# McBSP1 register map
Vendor: Texas Instruments
Peripheral module from a debugger description file (folder omap36xx).
Registers are 32-bit, access per field, reset values left out (the file's numbers can be read two ways) unless marked. A register's access mark holds for its fields unless they carry their own. Offsets are as the file gives them; lines under a group give offsets from that group; [hi:lo] are bit positions; {n}, {i} and the like mark numbered series; 'fields as' and 'values as' point back to an identical list; <NAME> marks a mode.

## McBSP1
0x00 MCBSPLP_DRR_REG ro — McBSPLP data receive register
  [31:0] DRR — Data receive register
0x08 MCBSPLP_DXR_REG wo — McBSPLP data transmit register
  [31:0] DXR — Data transmit register
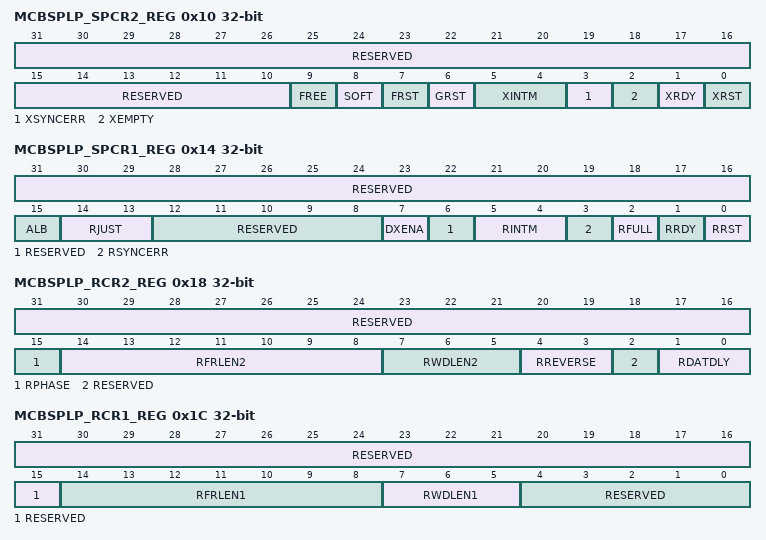
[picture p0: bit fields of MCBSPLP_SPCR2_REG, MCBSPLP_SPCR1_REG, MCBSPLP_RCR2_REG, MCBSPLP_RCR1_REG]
0x10 MCBSPLP_SPCR2_REG — McBSPLP serial port control register 2
  [31:10] RESERVED ro — Read returns 0x0.
  [9] FREE rw — Free Running Mode(When this bit is set, the module ignores the Msuspend input)
    0=Free running mode is disabled; 1=Free running mode is enabled
  [8] SOFT rw — Soft Bit
    0=SOFT Mode is disabled: the McBSP module stops its activity immediately following MSuspend assertion; 1=SOFT Mode is enabled: the McBSP module freezes its state after completion of the current operation when MSuspend is asserted
  [7] FRST rw — Frame-Sync Generator Reset
    0=Frame-synchronization logic is reset. Frame-sync signal FSG is not generated by the sample-rate generator; 1=Frame-sync signal FSG is generated after (FPER+1) number of CLKG clocks; i.e., all frame counters are loaded with their programmed values
  [6] GRST rw — Sample-Rate Generator Reset
    0=SRG is reset; 1=SRG is pulled out of reset. CLKG is driven as per programmed value in SRG registers (SRGR[1,2])
  [5:4] XINTM rw — Transmit Interrupt Mode (legacy)
    0=Transmit interrupt is driven by XRDY; 1=Transmit interrupt generated by end-of-frame; 2=Transmit interrupt generated by a new frame synchronization; 3=Transmit interrupt generated by XSYNCERR
  [3] XSYNCERR rw — Transmit Synchronization Error(writing 0 to this bit clear the legacy transmit interrupt if asserted due to XSYNCERROR condition)
    0=No synchronization error; 1=Synchronization error detected by McBSP
  [2] XEMPTY ro — Transmit Shift Register XSR Empty
    0=XSR is empty; 1=XSR is not empty
  [1] XRDY ro — Transmitter ready
    0=Transmitter is not ready; 1=Transmitter is ready for new data in DXR
  [0] XRST rw — Transmitter reset. This resets and enables the transmitter.
    0=The serial port transmitter is disabled and in reset state; 1=The serial port transmitter is enabled
0x14 MCBSPLP_SPCR1_REG — McBSPLP serial port control register 1
  [31:16] RESERVED ro — Read returns 0x0.
  [15] ALB rw — Analog loopback Mode
    0=Analog loopback mode disabled; 1=Analog loopback mode enabled
  [14:13] RJUST rw — Receive Sign-Extension and Justification Mode
    0=Right-justify and zero-fill MSBs in DRR; 1=Right-justify and sign-extend MSBs in DRR; 2=Left-justify and zero-fill LSBs in DRR
  [12:8] RESERVED ro — Read returns 0x0.
  [7] DXENA rw — DX Enabler
    0=DX enabler is off; 1=DX enabler is on
  [6] RESERVED ro — Read returns 0x0.
  [5:4] RINTM rw — Receive Interrupt Mode (legacy)
    0=Receive Interrupt driven by RRDY (i.e. end of word) and end of frame in A-bis mode; 1=Receive Interrupt generated by end-of-block or end-of-frame in multichannel operation; 2=Receive Interrupt generated by a new frame synchronization; 3=Receive Interrupt generated by RSYNCERR
  [3] RSYNCERR rw — Receive Synchronization Error(writing 0 to this bit clear the legacy receive interrupt if asserted due to RSYNCERROR condition)
    values as MCBSPLP_SPCR2_REG.XSYNCERR
  [2] RFULL ro — Receive Shift Register (RSR) Full
    0=DRR is not read, RB is full and RSR is also full with new word; 1=RB is not in overrun condition
  [1] RRDY ro — Receiver Ready
    0=Receiver is not ready; 1=Receiver is ready with data to be read from DRR
  [0] RRST rw — Receiver reset. This resets and enables the receiver.
    0=The serial port receiver is disabled and in reset state; 1=The serial port receiver is enabled
0x18 MCBSPLP_RCR2_REG — McBSPLP receive control register 2
  [31:16] RESERVED ro — Read returns 0x0.
  [15] RPHASE rw — Receive Phases
    0=Single-phase frame; 1=Dual-phase frame
  [14:8] RFRLEN2 rw — Receive Frame Length 2Single-phase frame selected: RFRLEN2=don't careDual-phase frame selected: RFRLEN2=000 0000 - 1 word per second phase (other values are reserved)
  [7:5] RWDLEN2 rw — Receive Word Length 2
    0=8 bits; 1=12 bits; 2=16 bits; 3=20 bits; 4=24 bits; 5=32 bits
  [4:3] RREVERSE rw — Receive reverse mode.
    0=Data transfer starts with MSB first; 1=Data transfer starts with LSB first
  [2] RESERVED ro — Read returns 0x0.
  [1:0] RDATDLY rw — Receive Data Delay
    0=0-bit data delay; 1=1-bit data delay; 2=2-bit data delay
0x1C MCBSPLP_RCR1_REG — McBSPLP receive control register 1
  [31:15] RESERVED ro — Read returns 0x0.
  [14:8] RFRLEN1 rw — Receive Frame Length 1Single-phase frame selected: RFRLEN1=000 0000 - 1 word per frameRFRLEN1=000 0001 - 2 words per frameRFRLEN1=111 1111 - 128 words per frameDual-phase frame selected: RFRLEN1=000 0000 - 1 word per phase(other values are reserved)
  [7:5] RWDLEN1 rw — Receive Word Length 1
    values as MCBSPLP_RCR2_REG.RWDLEN2
  [4:0] RESERVED ro — Read returns 0x0.
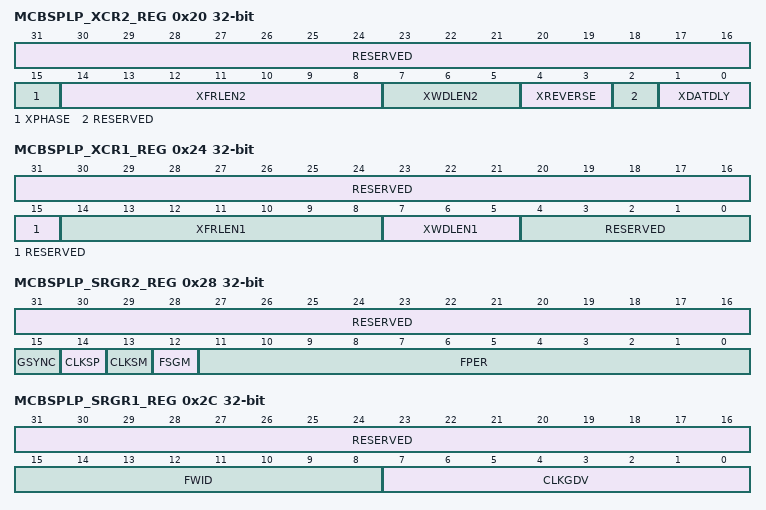
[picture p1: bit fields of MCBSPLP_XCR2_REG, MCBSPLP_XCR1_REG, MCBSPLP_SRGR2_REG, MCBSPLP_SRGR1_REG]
0x20 MCBSPLP_XCR2_REG — McBSPLP transmit control register 2
  [31:16] RESERVED ro — Read returns 0x0.
  [15] XPHASE rw — Transmit Phases
    0=Single-phase frame; 1=Dual-phase frame
  [14:8] XFRLEN2 rw — Transmit Frame Length 2Single-phase frame selected: XFRLEN2=don't careDual-phase frame selected: XFRLEN2=000 0000 - 1 word per second phase(other values are reserved)
  [7:5] XWDLEN2 rw — Transmit Word Length 2
    values as MCBSPLP_RCR2_REG.RWDLEN2
  [4:3] XREVERSE rw — Transmit reverse mode.
    values as MCBSPLP_RCR2_REG.RREVERSE
  [2] RESERVED ro — Read returns 0x0.
  [1:0] XDATDLY rw — Transmit Data Delay
    0=0-bit data delay; 1=1-bit data delay; 2=2-bit data delay
0x24 MCBSPLP_XCR1_REG — McBSPLP transmit control register 1
  [31:15] RESERVED ro — Read returns 0x0.
  [14:8] XFRLEN1 rw — Transmit Frame Length 1Single-phase frame selected:XFRLEN1=000 0000 - 1 word per frameXFRLEN1=000 0001 - 2 words per frameXFRLEN1=111 1111 - 128 words per frameDual-phase frame selected:XFRLEN1=000 0000 - 1 word per phase(other values are reserved)
  [7:5] XWDLEN1 rw — Transmit Word Length 1
    values as MCBSPLP_RCR2_REG.RWDLEN2
  [4:0] RESERVED ro — Read returns 0x0.
0x28 MCBSPLP_SRGR2_REG — McBSPLP SRG register 2
  [31:16] RESERVED ro — Read returns 0x0.
  [15] GSYNC rw — Sample Rate Generator SynchronizationOnly used when the external clock (CLKS) drives the SRG clock (CLKSM=0)
    0=The SRG clock (CLKG) is free running; 1=The SRG clock (CLKG) is running.But CLKG is resynchronized and frame-sync signal (FSG) is generated only after detecting the receive frame-synchronization signal (FSR). Also, frame period, FPER, is a don't care because the period is dictated by the external frame-sync pulse.
  [14] CLKSP rw — CLKS Polarity Clock Edge SelectOnly used when the external clock CLKS drives the SRG clock (CLKSM=0).
    0=Rising edge of CLKG and FSG; 1=Falling edge of CLKG and FSG
  [13] CLKSM rw — McBSP SRG Clock Mode
    0=SCLKME=0: SRG clock derived from the CLKS pin. SCLKME=1: SRG clock derived from the CLKR input pin.; 1=SCLKME=0: SRG clock derived from the McBSPi_ICLK clock. SCLKME=1: SRG clock derived from the CLKX input pin.
  [12] FSGM rw — Sample Rate Generator Transmit Frame-Synchronization Mode Used when FSXM=1 in the PCR.
    0=Transmit frame-sync signal (FSX) is generated when transmit buffer is not empty.When FSGM=0, FPER and FWID are used to determine the frame synchronization period and width (external FSX is gated by the buffer empty condition); 1=Transmit frame-sync signal driven by the SRG frame-sync signal, FSG
  [11:0] FPER rw — Frame Period. This value + 1 determines when the next frame-sync signal becomes active.Range: 1 to 4096 CLKG periods
0x2C MCBSPLP_SRGR1_REG — McBSPLP SRG register 1
  [31:16] RESERVED ro — Read returns 0x0.
  [15:8] FWID rw — Frame Width. This value + 1 determines the width of the frame-sync pulse, FSG, during its active period.Range: 1 to 256 CLKG periods.
  [7:0] CLKGDV rw — Sample Rate Generator Clock DividerThis value is used as the divide-down number to generate the required SRG clock frequency. Default value is 1.
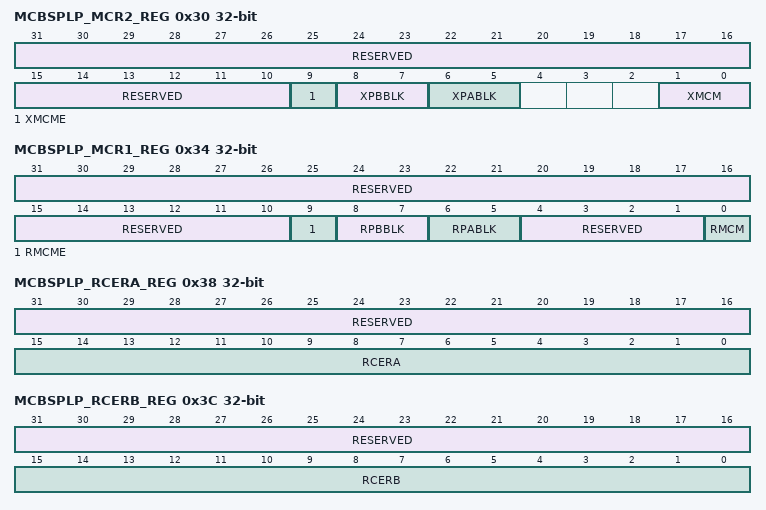
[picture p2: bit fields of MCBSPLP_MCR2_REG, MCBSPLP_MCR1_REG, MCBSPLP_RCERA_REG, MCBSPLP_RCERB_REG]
0x30 MCBSPLP_MCR2_REG — McBSPLP multi channel register 2
  [31:10] RESERVED ro — Read returns 0x0.
  [9] XMCME rw — Transmit multichannel partition mode determines whether only 32 channels or all 128 channels are to be individually selectable.XMCME is only applicable if channels can be individually disabled/enabled or masked/unmasked for transmission (XMCM is nonzero).
    0=2-partition mode: Only partitions A and B are used.You can control up to 32 channels in the transmit multichannel selection mode selected with the XMCM bits. If XMCM = 01b or 10b, assign 16 channels to partition A with the XPABLK bits. Assign 16 channels to partition B with the XPBBLK bits. If XMCM = 11b (for symmetric transmission and reception), assign 16 channels to receive partition A with the RPABLK bits. Assign 16 channels to receive partition B with the RPBBLK bits. You control the channels with the appropriate transmit channel enable registers: XCERA: Channels in partition A XCERB: Channels in partition B; 1=8-partition mode: All partitions (A through H) are used.You can control up to 128 channels in the transmit multichannel selection mode selected with the XMCM bits. You control the channels with the appropriate transmit channel enable registers: XCERA: Channels 0 through 15 XCERB: Channels 16 through 31 XCERC: Channels 32 through 47 XCERD: Channels 48 through 63 XCERE: Channels 64 through 79 XCERF: Channels 80 through 95 XCERG: Channels 96 through 111 XCERH: Channels 112 through 127
  [8:7] XPBBLK rw — Transmit Partition B Block(legacy)
    0=Block 1. Channel 16 to channel 31; 1=Block 3. Channel 48 to channel 63; 2=Block 5. Channel 80 to channel 95; 3=Block 7. Channel 112 to channel 127
  [6:5] XPABLK rw — Transmit Partition A Block(legacy)
    0=Block 0. Channel 0 to channel 15; 1=Block 2. Channel 32 to channel 47; 2=Block 4. Channel 64 to channel 79; 3=Block 6. Channel 96 to channel 111
  [1:0] XMCM rw — Transmit Multichannel Selection Enable
    0=All channels enabled without masking (DX is always driven during transmission of data); 1=All channels disabled and therefore masked by default.Required channels are selected by enabling XP(A/B)BLK and XCER(A/B) appropriately. Also, these selected channels are not masked and therefore DX is always driven.; 2=All channels enabled, but masked.Selected channels enabled via XP(A/B)BLK and XCER(A/B) are unmasked; 3=All channels disabled and therefore masked by default.Required channels are selected by enabling RP(A/B)BLK and RCER(A/B) appropriately. Selected channels can be unmasked by RP(A/B)BLK and XCER(A/B). This mode is used for symmetric transmit and receive operation.
0x34 MCBSPLP_MCR1_REG — McBSPLP multi channel register 1
  [31:10] RESERVED ro — Read returns 0x0.
  [9] RMCME rw — Receive multichannel partition mode determines whether only 32 channels or all 128 channels are to be individually selectable.RMCME is only applicable if channels can be individually enabled or disabled for reception (RMCM = 1).
    0=2-partition mode. Only partitions A and B are used.You can control up to 32 channels in the receive multichannel selection mode (RMCM = 1). Assign 16 channels to partition A with the RPABLK bits. Assign 16 channels to partition B with the RPBBLK bits. You control the channels with the appropriate receive channel enable registers: RCERA: Channels in partition A RCERB: Channels in partition B; 1=8-partition mode: All partitions (A through H) are used.You can control up to 128 channels in the receive multichannel selection mode. You control the channels with the appropriate receive channel enable registers: RCERA: Channels 0 through 15 RCERB: Channels 16 through 31 RCERC: Channels 32 through 47 RCERD: Channels 48 through 63 RCERE: Channels 64 through 79 RCERF: Channels 80 through 95 RCERG: Channels 96 through 111 RCERH: Channels 112 through 127
  [8:7] RPBBLK rw — Receive Partition B Block(legacy)
    values as MCBSPLP_MCR2_REG.XPBBLK
  [6:5] RPABLK rw — Receive Partition A Block(legacy)
    values as MCBSPLP_MCR2_REG.XPABLK
  [4:1] RESERVED ro — Read returns 0x0.
  [0] RMCM rw — Receive Multichannel Selection Enable
    0=All 128 channels; 1=All channels disabled by default.Required channels are selected by enabling RP(A/B)BLK and RCER(A/B) appropriately
0x38 MCBSPLP_RCERA_REG — McBSPLP receive channel enable register partition A
  [31:16] RESERVED ro — Read returns 0x0.
  [15:0] RCERA rw — Receive Channel EnableRCERA n=0 Disables reception of n-th channel in an even-numbered block in partition A . RCERA n=1 Enables reception of n-th channel in an even-numbered block in partition A .
0x3C MCBSPLP_RCERB_REG — McBSPLP receive channel enable register partition B
  [31:16] RESERVED ro — Read returns 0x0.
  [15:0] RCERB rw — Receive Channel EnableRCERB n=0 Disables reception of n-th channel in a even-numbered block in partition B . RCERB n=1 Enables reception of n-th channel in a even-numbered block in partition B .
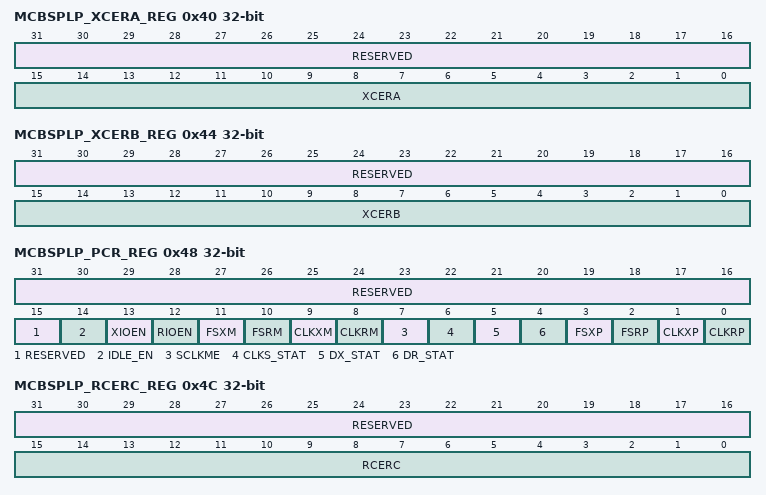
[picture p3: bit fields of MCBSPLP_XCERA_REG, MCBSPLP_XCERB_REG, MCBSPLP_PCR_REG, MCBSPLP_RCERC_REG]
0x40 MCBSPLP_XCERA_REG — McBSPLP transmit channel enable register partition A
  [31:16] RESERVED ro — Read returns 0x0.
  [15:0] XCERA rw — Transmit Channel EnableXCERA n=0 Disables transmission of n-th channel in an event-numbered block in partition A . XCERA n=1 Enables transmission of n-th channel in an event-numbered block in partition A .
0x44 MCBSPLP_XCERB_REG — McBSPLP transmit channel enable register partition B
  [31:16] RESERVED ro — Read returns 0x0.
  [15:0] XCERB rw — Transmit Channel EnableXCERB n=0 Disables transmission of n-th channel in an even-numbered block in partition B . XCERB n=1 Enables transmission of n-th channel in an even-numbered block in partition B .
0x48 MCBSPLP_PCR_REG — McBSPLP pin control register
  [31:15] RESERVED ro — Read returns 0x0.
  [14] IDLE_EN rw — Idle enable. This bit allows stopping all the clocks in the MCBSP module.(legacy)
    0=The McBSP is running; 1=The clocks in the McBSP are shut off when both IDLE_EN=1 and his power domain is in idle mode (Force idle or Smart idle)
  [13] XIOEN rw — Transmit General Purpose I/O Mode only when XRST=0 in SPCR[1,2](legacy)
    0=DX, FSX and CLKX are configured as serial port pins and do not function as general-purpose I/Os; 1=DX pin is a general purpose output. FSX and CLKX are general purpose I/Os. These serial port pins do not perform serial port operation.
  [12] RIOEN rw — Receive General Purpose I/O Mode when RRST=0 in SPCR[1,2](legacy)
    0=DR, FSR, CLKR and CLKS are configured as serial port pins and do not function as general-purpose I/Os; 1=DR and CLKS pins are general purpose inputs; FSR and CLKR are general purpose I/Os. These serial port pins do not perform serial port operation. The CLKS pin is affected by a combination of RRST and RIOEN signals of the receiver.
  [11] FSXM rw — Transmit Frame-Synchronization Mode
    0=Frame-synchronization signal derived from an external source; 1=Frame synchronization is determined by the SRG frame-synchronization mode bit FSGM in SRGR2
  [10] FSRM rw — Receive Frame-Synchronization Mode
    0=Frame-Synchronization pulses generated by an external device. FSR is an input pin.; 1=Frame synchronization generated internally by SRG. FSR is an output pin except when GSYNC=1 in SRGR.
  [9] CLKXM rw — Transmitter Clock ModeWhen digital loop-back mode set (McBSPi.MCBSPLP_XCCR_REG[5] DLB=1), CLKXM bit is ignored. The internal transmit clock (not the mcbspi_clkx pin) is driven by the internal SRG and mcbspi_clkx pin is in high-impedance.
    0=Transmitter clock is driven by an external clock with CLKX as an input pin; 1=CLKX is an output pin and is driven by the internal SRG
  [8] CLKRM rw — Receiver Clock ModeWhen digital loop-back mode set (McBSPi.MCBSPLP_XCCR_REG[5] DLB=1), CLKRM bit is ignored. The internal receive lock (not the mcbsp1_clkr pin) is driven by the internal SRG and mcbsp1_clkr pin is in high-impedance.
    0=Receive clock is an input driven by an external clock with CLKR as an input pin; 1=CLKR is an output pin and is driven by the internal SRG
  [7] SCLKME rw — The frequency of CLKG is:CLKG frequency = (Input clock frequency) / (CLKGDV + 1)SCLKME is used in conjunction with the CLKSM bit to select the input clock:
    0=CLKSM = 0: Signal on CLKS pin CLKSM = 1: McBSPi_ICLK clock; 1=CLKSM = 0: Signal on CLKR pin CLKSM = 1: Signal on CLKX pin
  [6] CLKS_STAT ro — CLKS pin status. Reflects value on CLKS pin when selected as a general purpose input.(legacy)
    0=The signal on the CLKS pin is low; 1=The signal on the CLKS pin is high
  [5] DX_STAT rw — DX pin status. Reflects value driven on to DX pin when selected as a general purpose output.(legacy)
    0=Drive the signal on the DX pin low; 1=Drive the signal on the DX pin high
  [4] DR_STAT ro — DR pin status. Reflects value on DR pin when selected as a general purpose input.(legacy)
    0=The signal on DR pin is low; 1=The signal on DR pin is high
  [3] FSXP rw — Transmit Frame-Synchronization Polarity
    0=Frame-synchronization pulse FSX is active high; 1=Frame-synchronization pulse FSX is active low
  [2] FSRP rw — Receive Frame-Synchronization Polarity
    0=Frame-synchronization pulse FSR is active high; 1=Frame-synchronization pulse FSR is active low
  [1] CLKXP rw — Transmit Clock Polarity
    0=Transmit data driven on rising edge of CLKX; 1=Transmit data driven on falling edge of CLKX
  [0] CLKRP rw — Receive Clock Polarity
    0=Receive data sampled on falling edge of CLKR; 1=Receive data sampled on rising edge of CLKR
0x4C MCBSPLP_RCERC_REG — McBSPLP receive channel enable register partition C
  [31:16] RESERVED ro — Read returns 0x0.
  [15:0] RCERC rw — Receive Channel EnableRCERC n=0 Disables reception of n-th channel in an even-numbered block in partition C . RCERC n=1 Enables reception of n-th channel in an even-numbered block in partition C .
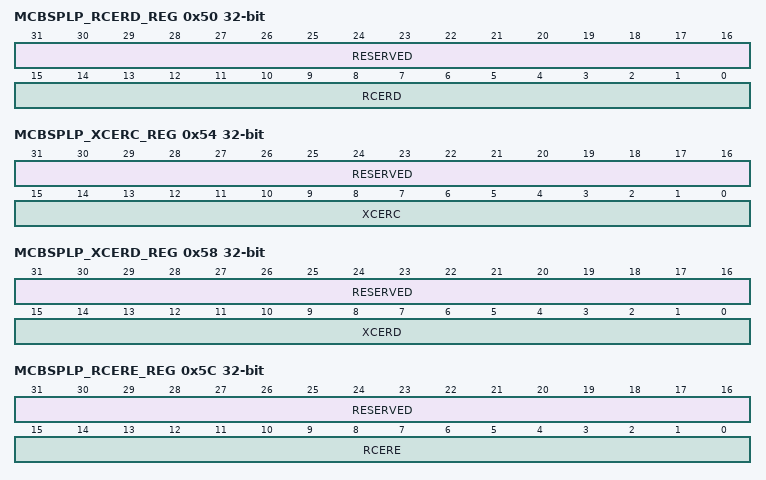
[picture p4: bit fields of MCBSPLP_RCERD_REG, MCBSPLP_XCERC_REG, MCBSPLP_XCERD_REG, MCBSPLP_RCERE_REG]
0x50 MCBSPLP_RCERD_REG — McBSPLP receive channel enable register partition D
  [31:16] RESERVED ro — Read returns 0x0.
  [15:0] RCERD rw — Receive Channel EnableRCERD n=0 Disables reception of n-th channel in an even-numbered block in partition D . RCERD n=1 Enables reception of n-th channel in an even-numbered block in partition D .
0x54 MCBSPLP_XCERC_REG — McBSPLP transmit channel enable register partition C
  [31:16] RESERVED ro — Read returns 0x0.
  [15:0] XCERC rw — Transmit Channel EnableXCERC n=0 Disables transmission of n-th channel in an event-numbered block in partition C . XCERC n=1 Enables transmission of n-th channel in an event-numbered block in partition C .
0x58 MCBSPLP_XCERD_REG — McBSPLP transmit channel enable register partition D
  [31:16] RESERVED ro — Read returns 0x0.
  [15:0] XCERD rw — Transmit Channel EnableXCERD n=0 Disables transmission of n-th channel in an even-numbered block in partition D . XCERD n=1 Enables transmission of n-th channel in an even-numbered block in partition D .
0x5C MCBSPLP_RCERE_REG — McBSPLP receive channel enable register partition E
  [31:16] RESERVED ro — Read returns 0x0.
  [15:0] RCERE rw — Receive Channel EnableRCERE n=0 Disables reception of n-th channel in an even-numbered block in partition E . RCERE n=1 Enables reception of n-th channel in an even-numbered block in partition E .
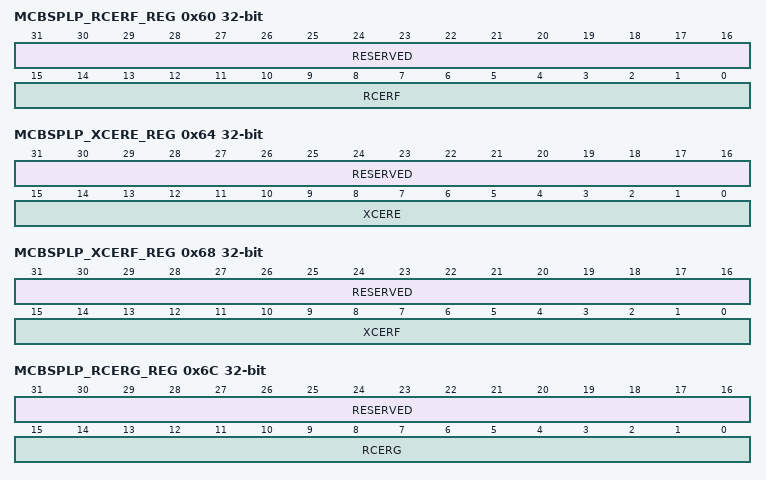
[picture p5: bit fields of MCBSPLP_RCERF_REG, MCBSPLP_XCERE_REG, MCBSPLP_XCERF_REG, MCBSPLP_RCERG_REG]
0x60 MCBSPLP_RCERF_REG — McBSPLP receive channel enable register partition F
  [31:16] RESERVED ro — Read returns 0x0.
  [15:0] RCERF rw — Receive Channel EnableRCERF n=0 Disables reception of n-th channel in an even-numbered block in partition F . RCERF n=1 Enables reception of n-th channel in an even-numbered block in partition F .
0x64 MCBSPLP_XCERE_REG — McBSPLP transmit channel enable register partition E
  [31:16] RESERVED ro — Read returns 0x0.
  [15:0] XCERE rw — Transmit Channel EnableXCERE n=0 Disables transmission of n-th channel in an event-numbered block in partition E . XCERE n=1 Enables transmission of n-th channel in an event-numbered block in partition E .
0x68 MCBSPLP_XCERF_REG — McBSPLP transmit channel enable register partition F
  [31:16] RESERVED ro — Read returns 0x0.
  [15:0] XCERF rw — Transmit Channel EnableXCERF n=0 Disables transmission of n-th channel in an even-numbered block in partition F . XCERF n=1 Enables transmission of n-th channel in an even-numbered block in partition F .
0x6C MCBSPLP_RCERG_REG — McBSPLP receive channel enable register partition G
  [31:16] RESERVED ro — Read returns 0x0.
  [15:0] RCERG rw — Receive Channel EnableRCERG n=0 Disables reception of n-th channel in an even-numbered block in partition G . RCERG n=1 Enables reception of n-th channel in an even-numbered block in partition G .
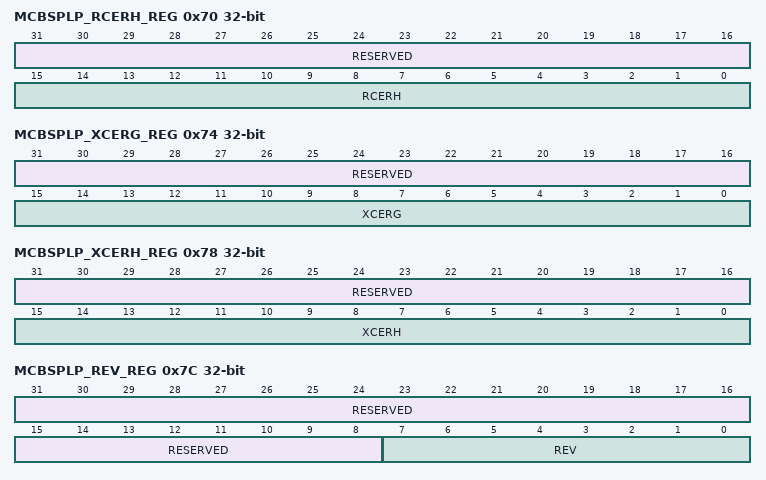
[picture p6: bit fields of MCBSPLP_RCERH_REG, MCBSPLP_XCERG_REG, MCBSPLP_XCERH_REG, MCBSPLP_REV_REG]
0x70 MCBSPLP_RCERH_REG — McBSPLP receive channel enable register partition H
  [31:16] RESERVED ro — Read returns 0x0.
  [15:0] RCERH rw — Receive Channel EnableRCERH n=0 Disables reception of n-th channel in an even-numbered block in partition H . RCERH n=1 Enables reception of n-th channel in an even-numbered block in partition H .
0x74 MCBSPLP_XCERG_REG — McBSPLP transmit channel enable register partition G
  [31:16] RESERVED ro — Read returns 0x0.
  [15:0] XCERG rw — Transmit Channel EnableXCERG n=0 Disables transmission of n-th channel in an event-numbered block in partition G . XCERG n=1 Enables transmission of n-th channel in an event-numbered block in partition G .
0x78 MCBSPLP_XCERH_REG — McBSPLP transmit channel enable register partition H
  [31:16] RESERVED ro — Read returns 0x0.
  [15:0] XCERH rw — Transmit Channel EnableXCERH n=0 Disables transmission of n-th channel in an even-numbered block in partition H . XCERH n=1 Enables transmission of n-th channel in an even-numbered block in partition H .
0x7C MCBSPLP_REV_REG ro — MCBSPLP Revision number register
  [31:8] RESERVED — Read returns 0x0.
  [7:0] REV — IP revision[7:4] Major revision . [3:0] Minor revision . examples: 0x10 for 1.0, 0x21 for 2.1 .
0x80 MCBSPLP_RINTCLR_REG rw — McBSPLP receive interrupt clear
  [31:0] RINTCLR — Read from this register will clear the IRQ generated by receive end-of-frame indication or mcbsp1_fsr detection.Write to this register has no effect.(legacy)
0x84 MCBSPLP_XINTCLR_REG rw — McBSPLP transmit interrupt clear (legacy)
  [31:0] XINTCLR — Read from this register will clear the IRQ generated by transmit end-of-frame indication or mcbspi_fsx detection (I=1:5).Write to this register has no effect.(legacy)
0x88 MCBSPLP_ROVFLCLR_REG rw — McBSPLP receive overflow interrupt clear
  [31:0] ROVFLCLR — Read from this register will clear the IRQ generated by the receive overflow condition.Write to this register has no effect.((legacy)
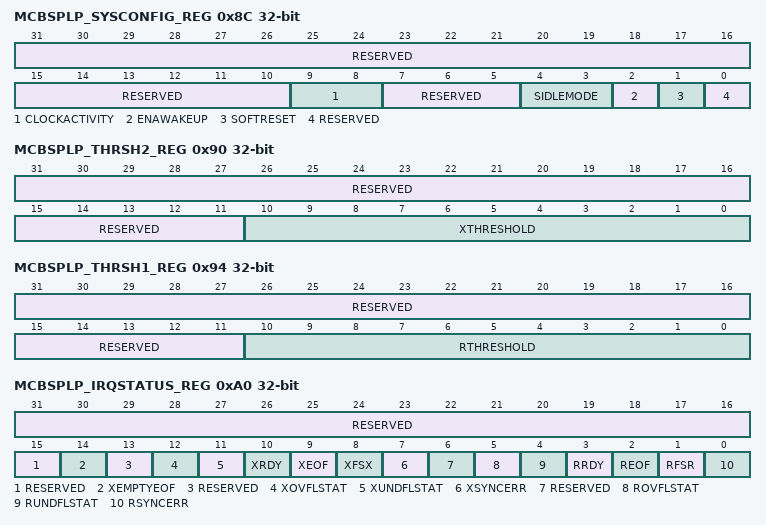
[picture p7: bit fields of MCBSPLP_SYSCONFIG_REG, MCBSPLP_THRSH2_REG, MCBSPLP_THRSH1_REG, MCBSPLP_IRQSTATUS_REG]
0x8C MCBSPLP_SYSCONFIG_REG — McBSPLP System Configuration register
  [31:10] RESERVED ro — Read returns 0x0.
  [9:8] CLOCKACTIVITY rw — 0x0: The McBSPi_ICLK clock can be switched off.The PRCM functional clock can be switched off.
    1=The McBSPi_ICLK clock must be maintained during wakeup.The PRCM functional clock can be switched off; 2=The McBSPi_ICLK clock can be switched off.The PRCM functional clock must be maintained during wakeup; 3=The McBSPi_ICLK clock must be maintained during wakeup.The PRCM functional clock must be maintained during wakeup
  [7:5] RESERVED ro — Read returns 0x0.
  [4:3] SIDLEMODE rw — Slave interface power management, idle request / acknowledge control:
    0=Force-idle. An idle request is acknowledged unconditionally.; 1=No-idle. An idle request is never acknowledged.; 2=Smart-idle. Acknowledgment to an idle request is given based on the internal activity of the module
  [2] ENAWAKEUP rw — Wake-up feature control:
    0=Wake-up is disabled; 1=Wake-up capability is enabled
  [1] SOFTRESET rw — McBSP global software reset
    0=NO soft reset; 1=Soft reset triggered
  [0] RESERVED ro — Read returns 0x0.
0x90 MCBSPLP_THRSH2_REG — McBSPLP transmit buffer threshold (DMA or IRQ trigger)
  [31:11] RESERVED ro — Read returns 0x0.
  [10:0] XTHRESHOLD rw — Transmit buffer threshold value. The DMA request (if enabled) of interrupt assertion (if enabled) is triggered if the number of free locations in the transmit buffer are above or equal to the XTHRESHOLD value + 1. Also, this value (XTHRESHOLD value + 1) indicates the number of words transferred during a transmit data DMA request, if transmit DMA is enabled.
0x94 MCBSPLP_THRSH1_REG — McBSPLP receive buffer threshold (DMA or IRQ trigger)
  [31:11] RESERVED ro — Read returns 0x0.
  [10:0] RTHRESHOLD rw — Receive buffer threshold value. The DMA request (if enabled) of interrupt assertion (if enabled)is triggered if the number of occupied locations in the receive buffer are above or equal to the RTHRESHOLD value + 1. Also, this value (RTHRESHOLD value + 1) indicates the number of words transferred during a receive data DMA request, if receive DMA is enabled.
0xA0 MCBSPLP_IRQSTATUS_REG — McBSPLP Interrupt Status register (OCP compliant IRQ line)
  [31:15] RESERVED ro — Read returns 0x0.
  [14] XEMPTYEOF rw — Transmit Buffer Empty at end of frame (XEMPTYEOF is set to one when a complete frame was transmitted and the transmit buffer is empty).Writing 1 to this bit clears the bit.
    0=Transmit buffer NOT Empty at end of frame; 1=Transmit buffer Empty at end of frame; Writing 1 to this bit clears the bit
  [13] RESERVED ro — Read returns 0x0.
  [12] XOVFLSTAT rw — Transmit Buffer Overflow (XOVFLSTAT bit is set to one when transmit buffer overflow; the data which is written while overflow condition is discarded).Writing 1 to this bit clears the bit.
    0=Transmit buffer NOT overflow; 1=Transmit buffer overflow; Writing 1 to this bit clears the bit
  [11] XUNDFLSTAT rw — Transmit Buffer Underflow (XUNDFLSTAT bit is set to one when the transmit data buffer is empty new data is required to be transmitted).Writing 1 to this bit clears the bit.
    0=the transmit data buffer is NOT empty new data is required to be transmitted; 1=the transmit data buffer is empty new data is required to be transmitted. Writing 1 to this bit clears the bit.
  [10] XRDY rw — Transmit Buffer Threshold Reached (XRDY bit is set to one when the transmit buffer free locations are equal or above the THRSH2_REG value).Writing 1 to this bit clears the bit.
    0=Transmit buffer occupied locations are below the THRSH2_REG value); 1=Transmit buffer occupied locations are equal or above the THRSH2_REG value). Writing 1 to this bit clears the bit.
  [9] XEOF rw — Transmit End Of Frame (XEOF is set to one when a complete frame was transmitted).Writing 1 to this bit clears the bit.
    0=complete frame was NOT transmitted; 1=complete frame was transmitted; Writing 1 to this bit clears the bit
  [8] XFSX rw — Transmit Frame Synchronization (XFSX bit is set to one when a new transmit frame synchronization is asserted).Writing 1 to this bit clears the bit.
    0=new transmit frame synchronization is NOT asserted; 1=new transmit frame synchronization is asserted; Writing 1 to this bit clears the bit
  [7] XSYNCERR rw — Transmit Frame Synchronization Error (XSYNCERR is set to one when a transmit frame synchronization error is detected).Writing 1 to this bit clears the bit.
    0=Transmit frame synchronization error is NOT detected; 1=Transmit frame synchronization error is detected. Writing 1 to this bit clears the bit.
  [6] RESERVED ro — Read returns 0x0.
  [5] ROVFLSTAT rw — Receive Buffer Overflow (ROVFLSTAT bit is set to one when receive buffer overflow; the data which is written while overflow condition is discarded).Writing 1 to this bit clears the bit.
    0=receive buffer NOT overflow; 1=receive buffer overflow; Writing 1 to this bit clears the bit
  [4] RUNDFLSTAT rw — Receive Buffer Underflow (RUNDFLSTAT bit is set to one when read operation is performed to the receive data register while receive buffer is empty; data read while underflow condition is undefined).Writing 1 to this bit clears the bit.
    0=read operation is performed to the receive data register while receive buffer is NOT empty; 1=read operation is performed to the receive data register while receive buffer is empty; Writing 1 to this bit clears the bit
  [3] RRDY rw — Receive Buffer Threshold Reached (RRDY bit is set to one when the receive buffer occupied locations are equal or above the THRSH1_REG value). Writing 1 to this bit clears the bit.
    0=receive buffer occupied locations are below the THRSH1_REG value); 1=receive buffer occupied locations are equal or above the THRSH1_REG value). Writing 1 to this bit clears the bit.
  [2] REOF rw — Receive End Of Frame (REOF is set to one when a complete frame was received).Writing 1 to this bit clears the bit.
    0=complete frame was NOT received; 1=complete frame was received; Writing 1 to this bit clears the bit
  [1] RFSR rw — Receive Frame Synchronization (RFSR bit is set to one when a new receive frame synchronization is asserted).Writing 1 to this bit clears the bit.
    0=new receive frame synchronization is NOT asserted; 1=new receive frame synchronization is asserted; Writing 1 to this bit clears the bit
  [0] RSYNCERR rw — Receive Frame Synchronization Error (RSYNCERR is set to one when a receive frame synchronization error is detected).Writing 1 to this bit clears the bit.
    0=receive frame synchronization error is NOT detected; 1=receive frame synchronization error is detected. Writing 1 to this bit clears the bit.
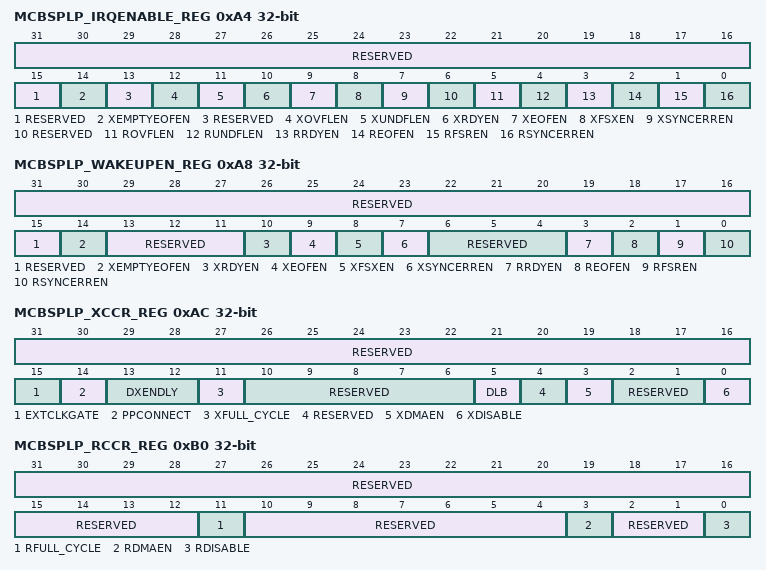
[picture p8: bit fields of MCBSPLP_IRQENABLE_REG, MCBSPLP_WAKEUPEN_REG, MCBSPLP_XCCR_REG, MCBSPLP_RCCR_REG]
0xA4 MCBSPLP_IRQENABLE_REG — McBSPLP Interrupt Enable register (OCP compliant IRQ line)
  [31:15] RESERVED ro — Read returns 0x0.
  [14] XEMPTYEOFEN rw — Transmit buffer empty at end of frame enable bit.
    0=Transmit buffer Empty at end of frame NOT enabled; 1=Transmit buffer Empty at end of frame enabled
  [13] RESERVED ro — Read returns 0x0.
  [12] XOVFLEN rw — Transmit Buffer Overflow enable bit.
    0=Transmit Buffer Overflow NOT enabled; 1=Transmit Buffer Overflow enabled
  [11] XUNDFLEN rw — Transmit Buffer Underflow enable bit.
    0=Transmit Buffer Underflow NOT enabled; 1=Transmit Buffer Underflow enabled
  [10] XRDYEN rw — Transmit Buffer Threshold Reached enable bit.
    0=Transmit Buffer Threshold Reached NOT enabled; 1=Transmit Buffer Threshold Reached enabled
  [9] XEOFEN rw — Transmit End Of Frame enable bit.
    0=Transmit End Of Frame NOT enabled; 1=Transmit End Of Frame enabled
  [8] XFSXEN rw — Transmit Frame Synchronization enable bit.
    0=Transmit Frame Synchronization NOT enabled; 1=Transmit Frame Synchronization enabled
  [7] XSYNCERREN rw — Transmit Frame Synchronization Error enable bit.
    0=Transmit Frame Synchronization Error NOT enabled; 1=Transmit Frame Synchronization Error enabled
  [6] RESERVED ro — Read returns 0x0.
  [5] ROVFLEN rw — Receive Buffer Overflow enable bit.
    0=Receive Buffer Overflow NOT enabled; 1=Receive Buffer Overflow enabled
  [4] RUNDFLEN rw — Receive Buffer Underflow enable bit.
    0=Receive Buffer Underflow NOT enabled; 1=Receive Buffer Underflow enabled
  [3] RRDYEN rw — Receive Buffer Threshold enable bit.
    0=Receive Buffer Threshold NOT enabled; 1=Receive Buffer Threshold enabled
  [2] REOFEN rw — Receive End Of Frame enable bit.
    0=Receive End Of Frame NOT enabled; 1=Receive End Of Frame enabled
  [1] RFSREN rw — Receive Frame Synchronization enable bit. RW
    0=Receive Frame Synchronization NOT enabled; 1=Receive Frame Synchronization enabled
  [0] RSYNCERREN rw — Receive Frame Synchronization Error enable bit.
    0=Receive Frame Synchronization Error NOT enabled; 1=Receive Frame Synchronization Error enabled
0xA8 MCBSPLP_WAKEUPEN_REG — McBSPLP Wakeup Enable register
  [31:15] RESERVED ro — Read returns 0x0.
  [14] XEMPTYEOFEN rw — Transmit buffer empty at end of frame WK enable bit.
    0=Transmit buffer Empty at end of frame WK enable is NOT active; 1=Transmit buffer Empty at end of frame WK enable is active
  [13:11] RESERVED ro — Read returns 0x0.
  [10] XRDYEN rw — Transmit Buffer Threshold Reached WK enable bit.
    0=Transmit Buffer Threshold WK enable is NOT active; 1=Transmit Buffer Threshold WK enable is active
  [9] XEOFEN rw — Transmit End Of Frame WK enable bit.
    0=Transmit End Of Frame WK enable is NOT active; 1=Transmit End Of Frame WK enable is active
  [8] XFSXEN rw — Transmit Frame Synchronization WK enable bit.
    0=Transmit Frame Synchronization WK enable is NOT active; 1=Transmit Frame Synchronization WK enable is active
  [7] XSYNCERREN rw — Transmit Frame Synchronization Error WK enable bit.
    0=Transmit Frame Synchronization Error WK enable is NOT active; 1=Transmit Frame Synchronization Error WK enable is active
  [6:4] RESERVED ro — Read returns 0x0.
  [3] RRDYEN rw — Receive Buffer Threshold wake-up enable bit.
    0=Receive Buffer Threshold WK enable is NOT active; 1=Receive Buffer Threshold WK enable is active
  [2] REOFEN rw — Receive End Of Frame WK enable bit.
    0=Receive End Of Frame WK enable is NOT active; 1=Receive End Of Frame WK enable is active
  [1] RFSREN rw — Receive Frame Synchronization WK enable bit.
    0=Receive Frame Synchronization WK enable is NOT active; 1=Receive Frame Synchronization WK enable is active
  [0] RSYNCERREN rw — Receive Frame Synchronization Error WK enable bit.
    0=Receive Frame Synchronization Error WK enable is NOT active; 1=Receive Frame Synchronization Error WK enable is active
0xAC MCBSPLP_XCCR_REG — McBSPLP transmit configuration control register
  [31:16] RESERVED ro — Read returns 0x0.
  [15] EXTCLKGATE rw — External clock gating enable (CLKX and FSX master only). When this bit is set and the transmit clock and FSX are set as output, the CLKX is enabled when FSX is active plus 3 clock cycles after (clock is provided for FWID + 4 clock cycles, assuming that the FSX width, active, is FWID + 1 clock cycles); outside this window the external transmit clock is gated. The receive use the same gated transmit clock and transmit frame synchronization signals regardless of the CLKRM/FSRM settings. When using this mode the frame synchronization signal must be active during reception of the entire frame (FWID must be programmed accordingly) to ensure the proper receive process, which requires at least 3 cycles after the frame complete to transfer the data into the receive buffer.
    0=External clock gating disabled; 1=External clock gating enable
  [14] PPCONNECT rw — Pair to pair connection. When set the DXENO pin is always set to 0, regardless of the frame boundary, setting the tree state buffer as output.
    0=non Pair-to-pair connection. The DX pin will go to high-impedance state when there is no frame to transmit.; 1=Pair-to-pair connection. When set, the DXENO pin is always set to 0, regardless of the frame boundary, setting the tree state buffer as output. This means the DX pin will be driven outside valid frame window. In that case, data sent by McBSP module during inactive channel are not guaranteed.
  [13:12] DXENDLY rw — When McBSPi.MCBSPLP_SPCR1_REG[7] DXENA bit is set to one, this field selects the added delay as follow:
    0=DXENDLY_0; 1=(default); 2=DXENDLY_2; 3=DXENDLY_3
  [11] XFULL_CYCLE rw — Transmit full cycle mode select:
    0=McBSP module operates in transmit half-cycle mode (transmit frame synchronization is sampled by the opposite edge of the clock used to drive transmit data); 1=McBSP module operates in transmit full-cycle mode (transmit frame synchronization is sampled by the same edge of the clock used to drive transmit data)
  [10:6] RESERVED ro — Read returns 0x0.
  [5] DLB rw — Digital Loop-Back
    0=No DLB; 1=DLB
  [4] RESERVED ro — Read returns 0x0.
  [3] XDMAEN rw — Transmit DMA Enable bit. When set to zero this bit will gate the external transmit DMA request, without resetting the DMA state machine. It is recommended to change this bit value only during transmit reset.
    0=When set to zero this bit will gate the external transmit DMA request,; 1=When set to one this bit will NOT gate the external transmit DMA request,
  [2:1] RESERVED ro — Read returns 0x0.
  [0] XDISABLE rw — Transmit Disable bit. When this bit is set the transmit process will stop at the next frame boundary.
    0=The transmit process will NOT stop at the next frame boundary; 1=The transmit process will stop at the next frame boundary
0xB0 MCBSPLP_RCCR_REG — McBSPLP receive configuration control register
  [31:12] RESERVED ro — Read returns 0x0.
  [11] RFULL_CYCLE rw — Receive full cycle mode select:
    0=McBSP module operates in receive half-cycle mode (receive frame synchronization is sampled by the opposite edge of the clock used to sample receive data); 1=McBSP module operates in receive full-cycle mode (receive frame synchronization is sampled by the same edge of the clock used to sample receive data)
  [10:4] RESERVED ro — Read returns 0x0.
  [3] RDMAEN rw — Receive DMA Enable bit. When set to zero this bit will gate the external transmit DMA request, without resetting the DMA state machine. It is recommended to change this bit value only during receive reset.
    0=When set to zero this bit will gate the external transmit DMA request; 1=When set to one this bit will NOT gate the external transmit DMA request
  [2:1] RESERVED ro — Read returns 0x0.
  [0] RDISABLE rw — Receive Disable bit. When this bit is set the receive process will stop at the next frame boundary.
    0=the receive process will NOT stop at the next frame boundary; 1=When this bit is set the receive process will stop at the next frame boundary
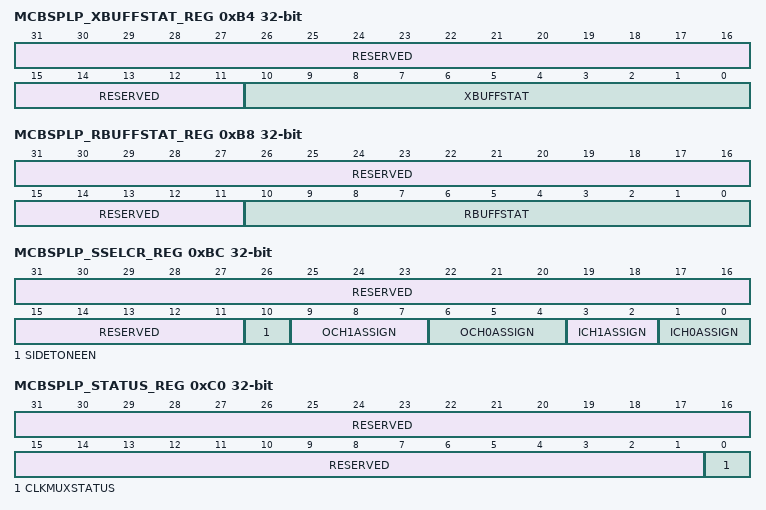
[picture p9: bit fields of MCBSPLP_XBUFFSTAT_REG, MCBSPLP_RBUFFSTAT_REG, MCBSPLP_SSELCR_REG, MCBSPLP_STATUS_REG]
0xB4 MCBSPLP_XBUFFSTAT_REG ro — McBSPLP transmit buffer status
  [31:11] RESERVED — Read returns 0x0.
  [10:0] XBUFFSTAT — Transmit Buffer Status (indicates the number of free locations in the transmit buffer). The XBUFFSTAT value reflects the buffer status on the L4 clock domain and it can be bigger than the real number of the free locations which are seen by the transmit state machine.
0xB8 MCBSPLP_RBUFFSTAT_REG ro — McBSPLP receive buffer status
  [31:11] RESERVED — Read returns 0x0.
  [10:0] RBUFFSTAT — Receive Buffer Status (indicates the number of occupied locations in the receive buffer). The RBUFFSTAT value reflects the buffer status on the L4 clock domain and it can be smaller than the real number of the occupied locations which are seen by the receive state machine.
0xBC MCBSPLP_SSELCR_REG — McBSPLP sidetone select register.
  [31:11] RESERVED ro — Read returns 0x0.
  [10] SIDETONEEN rw — Sidetone mode enable.
    0=Sidetone disabled; 1=Sidetone enabled
  [9:7] OCH1ASSIGN rw — Map the data for the speaker out channels to one of the McBSP channels (1 out of 8 channels)
  [6:4] OCH0ASSIGN rw — Map the data for the speaker out channels to one of the McBSP channels (1 out of 8 channels)
  [3:2] ICH1ASSIGN rw — Map the data from digital microphone channels to one of the McBSP channels (1 out of 4 channels)
  [1:0] ICH0ASSIGN rw — Map the data from digital microphone channels to one of the McBSP channels (1out of 4 channels)
0xC0 MCBSPLP_STATUS_REG ro — McBSPLP status register.
  [31:1] RESERVED — Read returns 0x0.
  [0] CLKMUXSTATUS — When going to/exiting from idle mode, the clock for the interface domain is switched between McBSP_ICLK and master serial clock to allow functioning in idle mode. This bit indicates that the status of clock switching and accesses to the McBSP registers are delayed during clock switching. To avoid such a situation, polling can be performed to status register to evaluate when McBSPLP is ready. This information is relevant only for the McBSPLPoperating in slave mode (serial clock provided by external component).
    0=McBSP registers can be accessed; 1=The response to a different register access is delayed until the muxing process is done. Only the[CLKMUXSTATUS] register can be accessed under this condition. The McBSP cannot exit from IDLE state (the external clock must be restarted).
